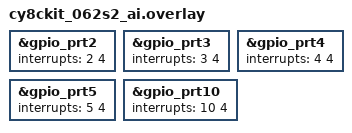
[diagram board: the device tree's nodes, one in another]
/*
 * Copyright (c) 2024 Arrow Electronics.
 *
 * SPDX-License-Identifier: Apache-2.0
 */

/* Changed default interrupts priority for GPIO to 4 */
&gpio_prt2 {
	interrupts = <2 4>;
};

&gpio_prt3 {
	interrupts = <3 4>;
};

&gpio_prt4 {
	interrupts = <4 4>;
};

&gpio_prt5 {
	interrupts = <5 4>;
};

&gpio_prt10 {
	interrupts = <10 4>;
};
